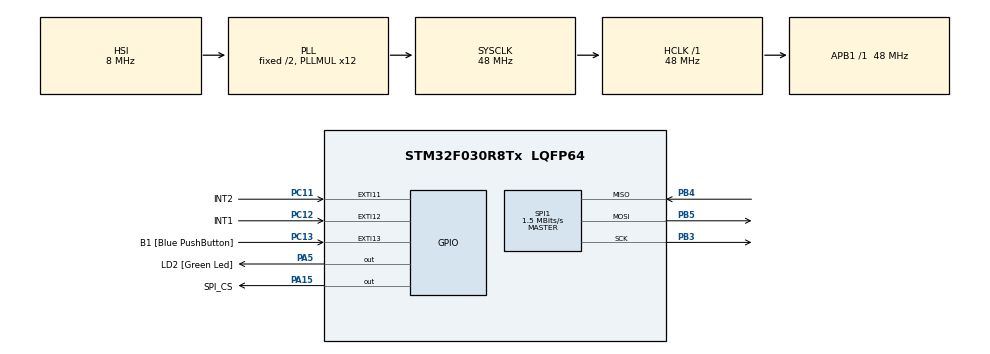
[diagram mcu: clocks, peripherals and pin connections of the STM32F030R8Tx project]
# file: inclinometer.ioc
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Mcu.Family=STM32F0
Mcu.Name=STM32F030R8Tx
Mcu.Package=LQFP64
NVIC.EXTI4_15_IRQn=true\:0\:0\:false\:false\:true
PA13.GPIO_Label=TMS
PA13.Mode=Serial_Wire
PA13.Signal=SYS_SWDIO
PA14.GPIO_Label=TCK
PA14.Mode=Serial_Wire
PA14.Signal=SYS_SWCLK
PA15.GPIO_Label=SPI_CS
PA15.Signal=GPIO_Output
PA2.GPIO_Label=USART_TX
PA2.GPIO_Mode=GPIO_MODE_AF_PP
PA2.GPIO_PuPd=GPIO_NOPULL
PA2.GPIO_Speed=GPIO_SPEED_FREQ_LOW
PA2.Signal=USART2_TX
PA3.GPIO_Label=USART_RX
PA3.GPIO_Mode=GPIO_MODE_AF_PP
PA3.GPIO_PuPd=GPIO_NOPULL
PA3.GPIO_Speed=GPIO_SPEED_FREQ_LOW
PA3.Signal=USART2_RX
PA5.GPIO_Label=LD2 [Green Led]
PA5.GPIO_Mode=GPIO_MODE_OUTPUT_PP
PA5.GPIO_PuPd=GPIO_NOPULL
PA5.GPIO_Speed=GPIO_SPEED_FREQ_LOW
PA5.Signal=GPIO_Output
PB3.Mode=Full_Duplex_Master
PB3.Signal=SPI1_SCK
PB4.Mode=Full_Duplex_Master
PB4.Signal=SPI1_MISO
PB5.Mode=Full_Duplex_Master
PB5.Signal=SPI1_MOSI
PC11.GPIO_Label=INT2
PC11.Signal=GPXTI11
PC12.GPIO_Label=INT1
PC12.Signal=GPXTI12
PC13.GPIO_Label=B1 [Blue PushButton]
PC13.GPIO_ModeDefaultEXTI=GPIO_MODE_EVT_RISING
PC13.Signal=GPXTI13
PC14-OSC32_IN.Signal=RCC_OSC32_IN
PC15-OSC32_OUT.Signal=RCC_OSC32_OUT
PF0-OSC_IN.Signal=RCC_OSC_IN
PF1-OSC_OUT.Signal=RCC_OSC_OUT
ProjectManager.HeapSize=0x200
ProjectManager.StackSize=0x400
ProjectManager.TargetToolchain=MDK-ARM V5
RCC.AHBFreq_Value=48000000
RCC.APB1Freq_Value=48000000
RCC.APB1TimFreq_Value=48000000
RCC.HCLKFreq_Value=48000000
RCC.PLLMUL=RCC_PLL_MUL12
RCC.SYSCLKFreq_VALUE=48000000
RCC.SYSCLKSource=RCC_SYSCLKSOURCE_PLLCLK
SPI1.BaudRatePrescaler=SPI_BAUDRATEPRESCALER_32
SPI1.CLKPhase=SPI_PHASE_2EDGE
SPI1.CLKPolarity=SPI_POLARITY_HIGH
SPI1.CalculateBaudRate=1.5 MBits/s
SPI1.DataSize=SPI_DATASIZE_8BIT
SPI1.Mode=SPI_MODE_MASTER
board=NUCLEO-F030R8

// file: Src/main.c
/**
  ******************************************************************************
  * File Name          : main.c
  * Description        : Main program body
  ******************************************************************************
  *
  * COPYRIGHT(c) 2016 STMicroelectronics
  *
  * Redistribution and use in source and binary forms, with or without modification,
  * are permitted provided that the following conditions are met:
  *   1. Redistributions of source code must retain the above copyright notice,
  *      this list of conditions and the following disclaimer.
  *   2. Redistributions in binary form must reproduce the above copyright notice,
  *      this list of conditions and the following disclaimer in the documentation
  *      and/or other materials provided with the distribution.
  *   3. Neither the name of STMicroelectronics nor the names of its contributors
  *      may be used to endorse or promote products derived from this software
  *      without specific prior written permission.
  *
  * THIS SOFTWARE IS PROVIDED BY THE COPYRIGHT HOLDERS AND CONTRIBUTORS "AS IS"
  * AND ANY EXPRESS OR IMPLIED WARRANTIES, INCLUDING, BUT NOT LIMITED TO, THE
  * IMPLIED WARRANTIES OF MERCHANTABILITY AND FITNESS FOR A PARTICULAR PURPOSE ARE
  * DISCLAIMED. IN NO EVENT SHALL THE COPYRIGHT HOLDER OR CONTRIBUTORS BE LIABLE
  * FOR ANY DIRECT, INDIRECT, INCIDENTAL, SPECIAL, EXEMPLARY, OR CONSEQUENTIAL
  * DAMAGES (INCLUDING, BUT NOT LIMITED TO, PROCUREMENT OF SUBSTITUTE GOODS OR
  * SERVICES; LOSS OF USE, DATA, OR PROFITS; OR BUSINESS INTERRUPTION) HOWEVER
  * CAUSED AND ON ANY THEORY OF LIABILITY, WHETHER IN CONTRACT, STRICT LIABILITY,
  * OR TORT (INCLUDING NEGLIGENCE OR OTHERWISE) ARISING IN ANY WAY OUT OF THE USE
  * OF THIS SOFTWARE, EVEN IF ADVISED OF THE POSSIBILITY OF SUCH DAMAGE.
  *
  ******************************************************************************
  */
#include "stm32f0xx_hal.h"
#include "spi.h"
#include "gpio.h"

/* USER CODE BEGIN Includes */
#include "defines.h"
#include "lis3dh_driver.h"
/* USER CODE END Includes */

/* USER CODE BEGIN PV */
/* Private variables ---------------------------------------------------------*/

/* USER CODE END PV */

void SystemClock_Config(void);
void Error_Handler(void);

/* USER CODE BEGIN PFP */
/* Private function prototypes -----------------------------------------------*/

/* USER CODE END PFP */

/* USER CODE BEGIN 0 */
extern AxesRaw_t leitura;
extern AxesRaw_t leitura_inicial;
extern float Angulo;
/* USER CODE END 0 */

int main(void)
{

  /* MCU Configuration----------------------------------------------------------*/

  /* Reset of all peripherals, Initializes the Flash interface and the Systick. */
  HAL_Init();

  /* Configure the system clock */
  SystemClock_Config();

  /* Initialize all configured peripherals */
  MX_GPIO_Init();
  MX_SPI1_Init();

  /* USER CODE BEGIN 2 */
	LIS3DH_Init();
  /* USER CODE END 2 */

  /* Infinite loop */
  while (1)
  {

  /* USER CODE BEGIN 3 */
		if(DataReady)
		{
			DataReady = 0;
			Angulo = GetAngle(leitura.AXIS_X,leitura.AXIS_Y,leitura.AXIS_Z,0,0,GRAVIDADE);
		}
  }
  /* USER CODE END 3 */

}

/** System Clock Configuration
*/
void SystemClock_Config(void)
{

  RCC_OscInitTypeDef RCC_OscInitStruct;
  RCC_ClkInitTypeDef RCC_ClkInitStruct;

  RCC_OscInitStruct.OscillatorType = RCC_OSCILLATORTYPE_HSI;
  RCC_OscInitStruct.HSIState = RCC_HSI_ON;
  RCC_OscInitStruct.HSICalibrationValue = 16;
  RCC_OscInitStruct.PLL.PLLState = RCC_PLL_ON;
  RCC_OscInitStruct.PLL.PLLSource = RCC_PLLSOURCE_HSI;
  RCC_OscInitStruct.PLL.PLLMUL = RCC_PLL_MUL12;
  RCC_OscInitStruct.PLL.PREDIV = RCC_PREDIV_DIV1;
  if (HAL_RCC_OscConfig(&RCC_OscInitStruct) != HAL_OK)
  {
    Error_Handler();
  }

  RCC_ClkInitStruct.ClockType = RCC_CLOCKTYPE_HCLK|RCC_CLOCKTYPE_SYSCLK
                              |RCC_CLOCKTYPE_PCLK1;
  RCC_ClkInitStruct.SYSCLKSource = RCC_SYSCLKSOURCE_PLLCLK;
  RCC_ClkInitStruct.AHBCLKDivider = RCC_SYSCLK_DIV1;
  RCC_ClkInitStruct.APB1CLKDivider = RCC_HCLK_DIV1;
  if (HAL_RCC_ClockConfig(&RCC_ClkInitStruct, FLASH_LATENCY_1) != HAL_OK)
  {
    Error_Handler();
  }

  HAL_SYSTICK_Config(HAL_RCC_GetHCLKFreq()/1000);

  HAL_SYSTICK_CLKSourceConfig(SYSTICK_CLKSOURCE_HCLK);

  /* SysTick_IRQn interrupt configuration */
  HAL_NVIC_SetPriority(SysTick_IRQn, 0, 0);
}

/* USER CODE BEGIN 4 */
void HAL_GPIO_EXTI_Callback(uint16_t GPIO_Pin)
{
	if(GPIO_Pin == INT1_Pin)
	{
		LIS3DH_INT1_ISR();
	}
	if(GPIO_Pin == INT2_Pin)
	{
		LIS3DH_INT2_ISR();
	}
}
/* USER CODE END 4 */

void Error_Handler(void)
{
  while(1)
  {
  }
}

/************************ (C) COPYRIGHT STMicroelectronics *****END OF FILE****/
